# STM32H5E5xx register map
File version: 1.0
Registers are 32-bit, read-write, reset 0x0 unless marked. A register's access mark holds for its fields unless they carry their own. Offsets are from the block's base; [hi:lo] are bit positions; {n}, {i} and the like mark numbered series.

## RAMCFG_BKPRAM — SRAMs configuration controller
Base 0x40026100
Same registers: RAMCFG_BKPRAM_S 0x50026100
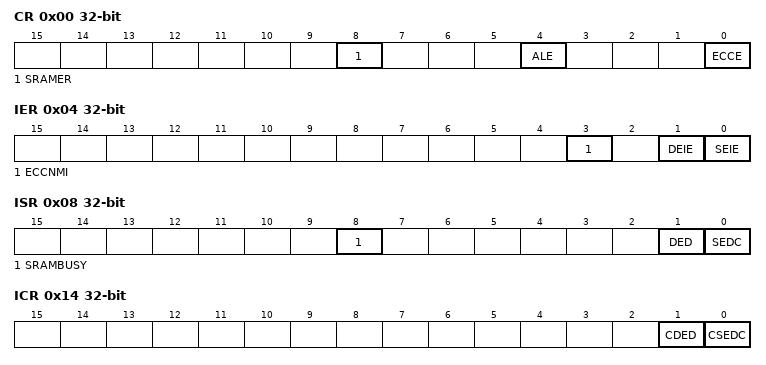
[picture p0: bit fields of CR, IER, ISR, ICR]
0x00 CR — Control Register
  [8] SRAMER — Start Erase
  [4] ALE — Address Latching Enable
  [0] ECCE — ECC Enable
0x04 IER — Interrupt Enable Register
  [3] ECCNMI — NMI redirection interrupt
  [1] DEIE — Double Error Interrupt Enable
  [0] SEIE — Single Error Interrupt Enable
0x08 ISR — Interrupt Status Register
  [8] SRAMBUSY — SRAM busy flag
  [1] DED — Double Error Detected flag
  [0] SEDC — Single Error Detected and Corrected flag
0x0C SEAR — ECC Single Error Address Register
  [31:0] ESEA — ECC Single Error Address
0x10 DEAR — ECC Double Error Address Register
  [31:0] EDEA — ECC Double Error Address
0x14 ICR — Interrupt Clear Register
  [1] CDED — Clear ECC Double Error Detected Flag
  [0] CSEDC — Clear ECC Single Error Detected and Corrected Flag
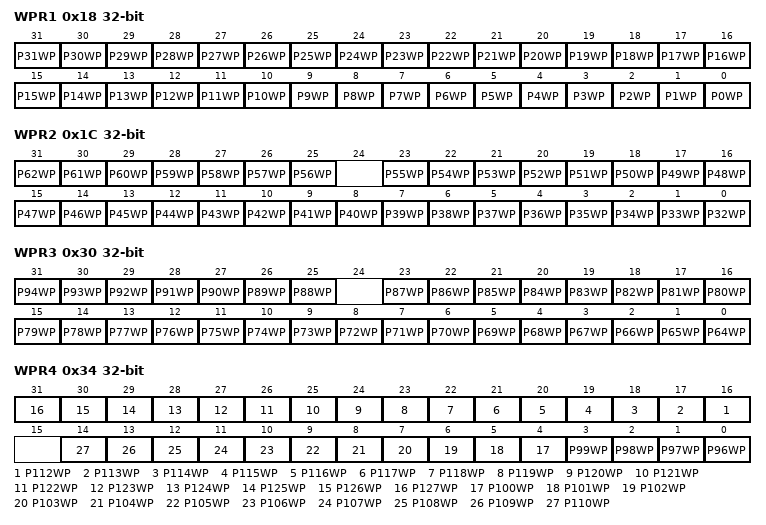
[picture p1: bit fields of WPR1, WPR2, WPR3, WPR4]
0x18 WPR1 — SRAM Write Protection Register 1
  [n] P{n}WP (n=0..31) — Write Protection Page {n:02}
0x1C WPR2 — SRAM Write Protection Register 2
  [n-31] P{n}WP (n=56..62) — Write Protection Page {n}
  [n-32] P{n}WP (n=32..55) — Write Protection Page {n}
0x24 ECCKEY — SRAM ECC Key Register
0x28 ERKEYR — SRAM Erase Key Register
  [7:0] ERASEKEY — Erase Write Protection Key
0x30 WPR3 — SRAM Write Protection Register 3
  [n-63] P{n}WP (n=88..94) — Write Protection Page {n}
  [n-64] P{n}WP (n=64..87) — Write Protection Page {n}
0x34 WPR4 — SRAM Write Protection Register 4
  [n-96] P{n}WP (n=112..127) — Write Protection Page {n}
  [n-96] P{n}WP (n=96..110) — Write Protection Page {n}

## ICACHE — Instruction Cache
Base 0x40030400
Same registers: ICACHE_S 0x50030400
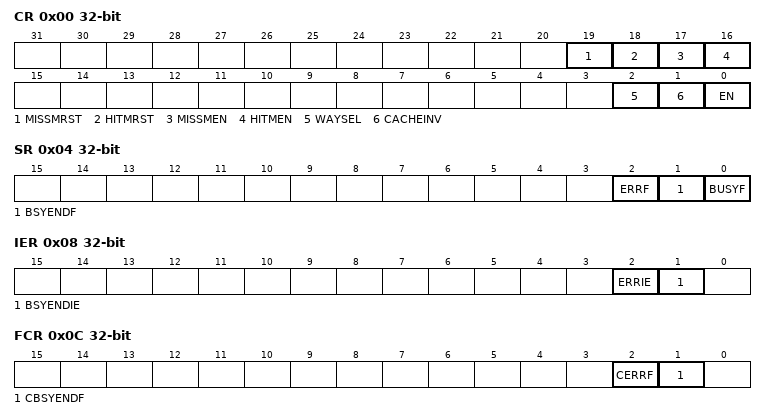
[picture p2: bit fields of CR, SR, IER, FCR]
0x00 CR — ICACHE control register
  [19] MISSMRST — Miss monitor reset
  [18] HITMRST — Hit monitor reset
  [17] MISSMEN — Miss monitor enable
  [16] HITMEN — Hit monitor enable
  [2] WAYSEL — Ways selection
    0=ICACHE_1WAY (1-way cache (direct mapped cache)); 1=ICACHE_2WAYS (2-ways set associative cache (default))
  [1] CACHEINV — Cache invalidation
  [0] EN — Enable
0x04 SR — ICACHE status register
  [2] ERRF — Cache error flag
  [1] BSYENDF — Busy end flag
  [0] BUSYF — Busy flag
0x08 IER — ICACHE interrupt enable register
  [2] ERRIE — Cache error interrupt enable
  [1] BSYENDIE — Busy end interrupt enable
0x0C FCR — ICACHE Flag clear register
  [2] CERRF — Cache error flag clear
  [1] CBSYENDF — Busy end flag clear
0x10 HMONR — ICACHE hit monitor register
  [31:0] HITMON — Cache hit monitor register
0x14 MMONR — ICACHE miss monitor register
  [15:0] MISSMON — Cache miss monitor register
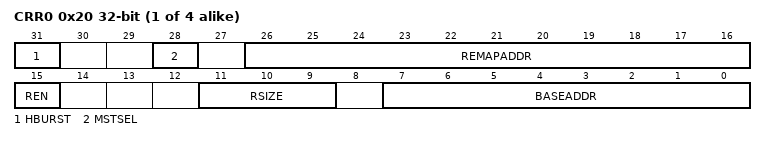
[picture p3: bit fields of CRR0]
{0x20+4i} CRR{i} (i=0..3) — ICACHE region {i} configuration register
  [31] HBURST — Region X output burst type
  [28] MSTSEL — Region X AHB cache master selection
  [26:16] REMAPADDR — Remap address of Region X to be remapped
  [15] REN — Region X enable
  [11:9] RSIZE — Region X size
  [7:0] BASEADDR — Base address of region X to remap

## DCACHE1 — Data Cache
Base 0x40031400
Same registers: DCACHE1_S 0x50031400
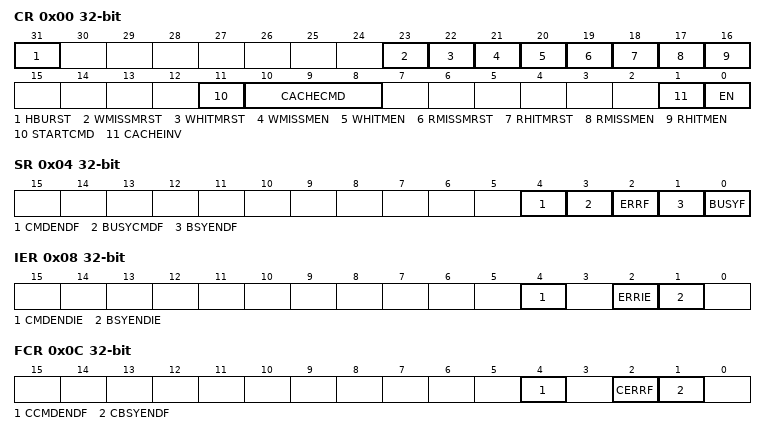
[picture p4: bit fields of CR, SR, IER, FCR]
0x00 CR — DCACHE control register
  [31] HBURST — Read burst type
    0=WRAP; 1=INCR
  [23] WMISSMRST — Write Miss monitor reset
  [22] WHITMRST — Write Hit monitor reset
  [21] WMISSMEN — Write Miss monitor enable
  [20] WHITMEN — Write Hit monitor enable
  [19] RMISSMRST — Read Miss monitor reset
  [18] RHITMRST — Read Hit monitor reset
  [17] RMISSMEN — Read Miss monitor enable
  [16] RHITMEN — Read Hit monitor enable
  [11] STARTCMD — Start command
  [10:8] CACHECMD — Cache command
    2=INVALIDATE_BY_ADDR; 1=CLEAN_BY_ADDR; 3=CLEAN_INVALIDATE_BY_ADDR; 0=NO_OPERATION
  [1] CACHEINV — Cache invalidation
  [0] EN — Enable
0x04 SR — DCACHE status register
  [4] CMDENDF — Command end flag
  [3] BUSYCMDF — Busy command flag
  [2] ERRF — Cache error flag
  [1] BSYENDF — Busy end flag
  [0] BUSYF — Busy flag
0x08 IER — DCACHE interrupt enable register
  [4] CMDENDIE — Command end interrupt enable
  [2] ERRIE — Cache error interrupt enable
  [1] BSYENDIE — Busy end interrupt enable
0x0C FCR — DCACHE Flag clear register
  [4] CCMDENDF — Command end flag clear
  [2] CERRF — Cache error flag clear
  [1] CBSYENDF — Busy end flag clear
0x10 RHMONR — DCACHE Read hit monitor register
  [31:0] RHITMON — Cache Read hit monitor register
0x14 RMMONR — DCACHE Read miss monitor register
  [15:0] RMISSMON — Cache Read miss monitor register
0x20 WHMONR — DCACHE Write hit monitor register
  [31:0] WHITMON — Cache Read hit monitor register
0x24 WMMONR — DCACHE Write miss monitor register
  [15:0] WMISSMON — Cache Read miss monitor register
0x28 CMDRSADDRR — DCACHE Command Start Address register
  [31:4] CMDSTARTADDR — Command start address
0x2C CMDREADDRR — DCACHE Command End Address register
  [31:4] CMDENDADDR — Command end address
